# haltium_ppr register map
Vendor: Nordic Semiconductor; Series: nRFHaltium; File version: 1
Registers are 32-bit, read-write, reset 0x0 unless marked. A register's access mark holds for its fields unless they carry their own. Offsets are from the block's base; [hi:lo] are bit positions; lines under a group give offsets from that group; {n}, {i} and the like mark numbered series; 'fields as' and 'values as' point back to an identical list.

## GLOBAL_TSGEN_NS — GENERIC 0
Base 0xBF041000
Same registers: GLOBAL_CAN_NS 0x4F8D5000, GLOBAL_CAN_S 0x5F8D5000, GLOBAL_ETB_NS 0xBF044000, GLOBAL_ETR_NS 0xBF045000
0x00 TASKS_GENERICTASK wo — Generic event
  [0] TASKS_GENERICTASK
    1=Trigger task
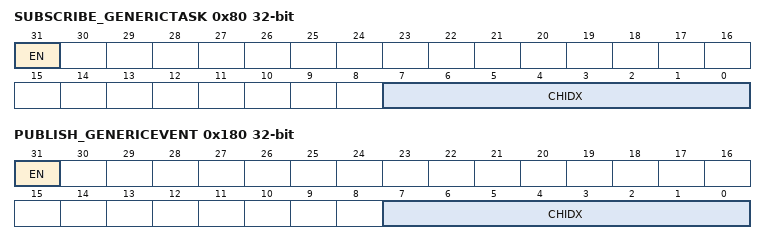
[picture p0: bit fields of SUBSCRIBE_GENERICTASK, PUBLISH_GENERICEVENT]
0x80 SUBSCRIBE_GENERICTASK — Subscribe configuration for task GENERICTASK
  [31] EN
    0=Disabled (Disable subscription); 1=Enabled (Enable subscription)
  [7:0] CHIDX — DPPI channel that task GENERICTASK will subscribe to
0x100 EVENTS_GENERICEVENT — Generic event
  [0] EVENTS_GENERICEVENT
    0=NotGenerated (Event not generated); 1=Generated (Event generated)
0x180 PUBLISH_GENERICEVENT — Publish configuration for event GENERICEVENT
  [31] EN
    0=Disabled (Disable publishing); 1=Enabled (Enable publishing)
  [7:0] CHIDX — DPPI channel that event GENERICEVENT will publish to
0x300 INTEN — Enable or disable interrupt
  [0] GENERICEVENT — Enable or disable interrupt for event GENERICEVENT
    0=Disabled; 1=Enabled
0x304 INTENSET — Enable interrupt
  [0] GENERICEVENT — Write '1' to enable interrupt for event GENERICEVENT
    on read: 0=Disabled (Read: Disabled); 1=Enabled (Read: Enabled) | on write: 1=Set (Enable)
0x308 INTENCLR — Disable interrupt
  [0] GENERICEVENT — Write '1' to disable interrupt for event GENERICEVENT
    on read: 0=Disabled (Read: Disabled); 1=Enabled (Read: Enabled) | on write: 1=Clear (Disable)

## GLOBAL_IPCT120_NS — IPCT APB registers 0
Base 0x4F8D1000
Same registers: GLOBAL_IPCT130_NS 0x4F921000, GLOBAL_IPCT120_S 0x5F8D1000, GLOBAL_IPCT130_S 0x5F921000
{0x0+4i} TASKS_SEND[{i}] (i=0..7) wo — Description collection: Trigger event on IPCT source channel n
  [0] TASKS_SEND — Trigger event on IPCT source channel n
    1=Trigger task
{0x40+4i} TASKS_ACK[{i}] (i=0..7) wo — Description collection: Acknowledge RECEIVE event on IPCT sink channel n
  [0] TASKS_ACK — Acknowledge RECEIVE event on IPCT sink channel n
    1=Trigger task
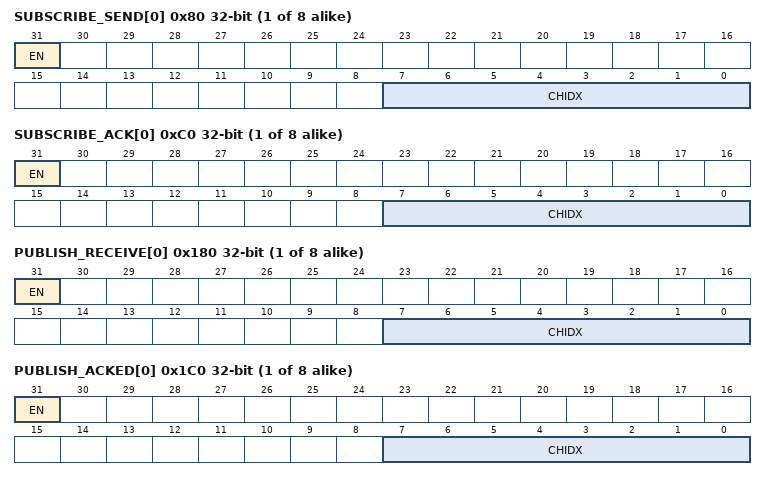
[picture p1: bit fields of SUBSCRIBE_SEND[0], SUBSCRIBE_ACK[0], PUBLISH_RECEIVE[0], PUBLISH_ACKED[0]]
{0x80+4i} SUBSCRIBE_SEND[{i}] (i=0..7) — Description collection: Subscribe configuration for task SEND[n]
  [31] EN
    0=Disabled (Disable subscription); 1=Enabled (Enable subscription)
  [7:0] CHIDX — DPPI channel that task SEND[n] will subscribe to
{0xC0+4i} SUBSCRIBE_ACK[{i}] (i=0..7) — Description collection: Subscribe configuration for task ACK[n]
  [31] EN
    values as SUBSCRIBE_SEND[0].EN
  [7:0] CHIDX — DPPI channel that task ACK[n] will subscribe to
{0x100+4i} EVENTS_RECEIVE[{i}] (i=0..7) — Description collection: Event received on IPCT sink channel n
  [0] EVENTS_RECEIVE — Event received on IPCT sink channel n
    0=NotGenerated (Event not generated); 1=Generated (Event generated)
{0x140+4i} EVENTS_ACKED[{i}] (i=0..7) — Description collection: SEND task on IPCT source channel n was acknowledged
  [0] EVENTS_ACKED — SEND task on IPCT source channel n was acknowledged
    values as EVENTS_RECEIVE[0].EVENTS_RECEIVE
{0x180+4i} PUBLISH_RECEIVE[{i}] (i=0..7) — Description collection: Publish configuration for event RECEIVE[n]
  [31] EN
    0=Disabled (Disable publishing); 1=Enabled (Enable publishing)
  [7:0] CHIDX — DPPI channel that event RECEIVE[n] will publish to
{0x1C0+4i} PUBLISH_ACKED[{i}] (i=0..7) — Description collection: Publish configuration for event ACKED[n]
  [31] EN
    values as PUBLISH_RECEIVE[0].EN
  [7:0] CHIDX — DPPI channel that event ACKED[n] will publish to
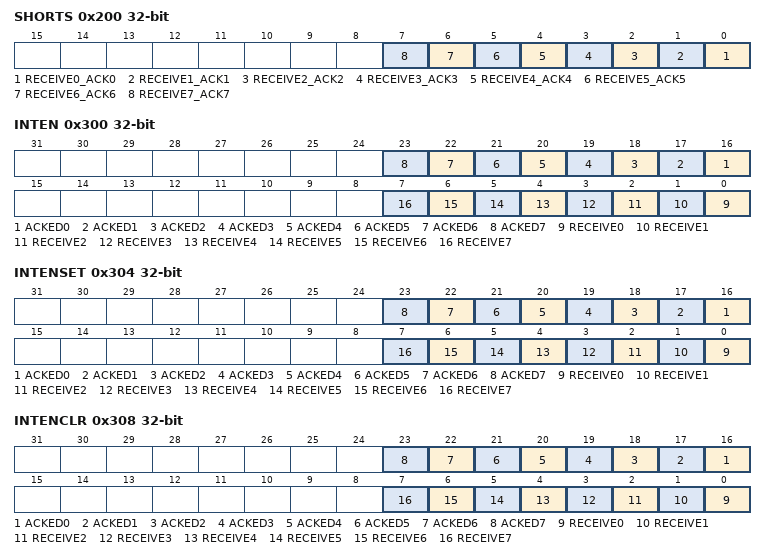
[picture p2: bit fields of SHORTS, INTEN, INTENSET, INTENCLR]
0x200 SHORTS — Shortcuts between local events and tasks
  [all] fields
    0=Disabled (Disable shortcut); 1=Enabled (Enable shortcut)
  [n] RECEIVE{n}_ACK{n} (n=0..7) — Shortcut between event RECEIVE[{n}] and task ACK[{n}]
0x300 INTEN — Enable or disable interrupt
  [all] fields
    0=Disabled; 1=Enabled
  [n+16] ACKED{n} (n=0..7) — Enable or disable interrupt for event ACKED[{n}]
  [n] RECEIVE{n} (n=0..7) — Enable or disable interrupt for event RECEIVE[{n}]
0x304 INTENSET — Enable interrupt
  [all] fields
    on read: 0=Disabled (Read: Disabled); 1=Enabled (Read: Enabled) | on write: 1=Set (Enable)
  [n+16] ACKED{n} (n=0..7) — Write '1' to enable interrupt for event ACKED[{n}]
  [n] RECEIVE{n} (n=0..7) — Write '1' to enable interrupt for event RECEIVE[{n}]
0x308 INTENCLR — Disable interrupt
  [all] fields
    on read: 0=Disabled (Read: Disabled); 1=Enabled (Read: Enabled) | on write: 1=Clear (Disable)
  [n+16] ACKED{n} (n=0..7) — Write '1' to disable interrupt for event ACKED[{n}]
  [n] RECEIVE{n} (n=0..7) — Write '1' to disable interrupt for event RECEIVE[{n}]
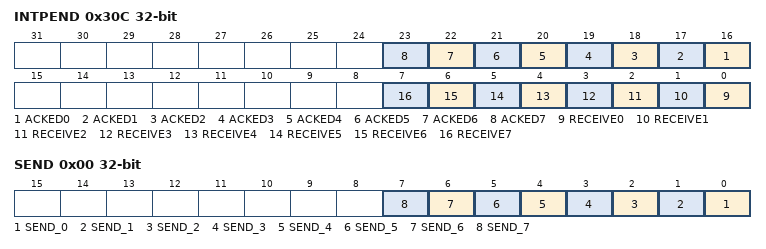
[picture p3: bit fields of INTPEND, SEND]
0x30C INTPEND ro — Pending interrupts
  [all] fields
    on read: 0=NotPending (Read: Not pending); 1=Pending (Read: Pending)
  [n+16] ACKED{n} (n=0..7) — Read pending status of interrupt for event ACKED[{n}]
  [n] RECEIVE{n} (n=0..7) — Read pending status of interrupt for event RECEIVE[{n}]
0x400 OVERFLOW group — Unspecified
  0x00 SEND — Overflow status for SEND tasks Write 0 to clear
    [all] fields
      1=Overflow (Task overflow has happened); 0=NoOverflow (Task overflow has not happened)
    [n] SEND_{n} (n=0..7) — Overflow status for SEND[{n}] task

## Notices in the file
Copyright (c) 2010 - 2021, Nordic Semiconductor ASA
All rights reserved.
Redistribution and use in source and binary forms, with or without modification,
are permitted provided that the following conditions are met:
1. Redistributions of source code must retain the above copyright notice, this
list of conditions and the following disclaimer.
2. Redistributions in binary form, except as embedded into a Nordic
Semiconductor ASA integrated circuit in a product or a software update for
such product, must reproduce the above copyright notice, this list of
conditions and the following disclaimer in the documentation and/or other
materials provided with the distribution.
3. Neither the name of Nordic Semiconductor ASA nor the names of its
contributors may be used to endorse or promote products derived from this
software without specific prior written permission.
4. This software, with or without modification, must only be used with a
Nordic Semiconductor ASA integrated circuit.
5. Any software provided in binary form under this license must not be reverse
engineered, decompiled, modified and/or disassembled.
THIS SOFTWARE IS PROVIDED BY NORDIC SEMICONDUCTOR ASA "AS IS" AND ANY EXPRESS
OR IMPLIED WARRANTIES, INCLUDING, BUT NOT LIMITED TO, THE IMPLIED WARRANTIES
OF MERCHANTABILITY, NONINFRINGEMENT, AND FITNESS FOR A PARTICULAR PURPOSE ARE
DISCLAIMED. IN NO EVENT SHALL NORDIC SEMICONDUCTOR ASA OR CONTRIBUTORS BE
LIABLE FOR ANY DIRECT, INDIRECT, INCIDENTAL, SPECIAL, EXEMPLARY, OR
CONSEQUENTIAL DAMAGES (INCLUDING, BUT NOT LIMITED TO, PROCUREMENT OF SUBSTITUTE
GOODS OR SERVICES; LOSS OF USE, DATA, OR PROFITS; OR BUSINESS INTERRUPTION)
HOWEVER CAUSED AND ON ANY THEORY OF LIABILITY, WHETHER IN CONTRACT, STRICT
LIABILITY, OR TORT (INCLUDING NEGLIGENCE OR OTHERWISE) ARISING IN ANY WAY OUT
OF THE USE OF THIS SOFTWARE, EVEN IF ADVISED OF THE POSSIBILITY OF SUCH DAMAGE.
